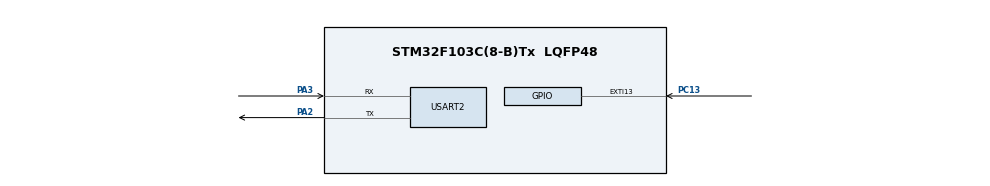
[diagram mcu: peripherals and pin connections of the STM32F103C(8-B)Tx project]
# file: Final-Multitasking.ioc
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Dma.Request0=USART2_RX
Dma.USART2_RX.0.Direction=DMA_PERIPH_TO_MEMORY
Dma.USART2_RX.0.Instance=DMA1_Channel6
Dma.USART2_RX.0.MemDataAlignment=DMA_MDATAALIGN_BYTE
Dma.USART2_RX.0.MemInc=DMA_MINC_ENABLE
Dma.USART2_RX.0.Mode=DMA_NORMAL
Dma.USART2_RX.0.PeriphDataAlignment=DMA_PDATAALIGN_BYTE
Dma.USART2_RX.0.PeriphInc=DMA_PINC_DISABLE
Dma.USART2_RX.0.Priority=DMA_PRIORITY_LOW
FREERTOS.Tasks01=defaultTask,0,128,StartDefaultTask,Default,NULL,Dynamic,NULL,NULL
Mcu.Family=STM32F1
Mcu.Name=STM32F103C(8-B)Tx
Mcu.Package=LQFP48
NVIC.DMA1_Channel6_IRQn=true\:5\:0\:false\:false\:true\:true\:false\:true\:true
NVIC.PriorityGroup=NVIC_PRIORITYGROUP_4
NVIC.TIM4_IRQn=true\:15\:0\:false\:false\:true\:false\:false\:true\:true
NVIC.TimeBase=TIM4_IRQn
NVIC.TimeBaseIP=TIM4
NVIC.USART2_IRQn=true\:5\:0\:false\:false\:true\:true\:true\:true\:true
PA13.Mode=Serial_Wire
PA13.Signal=SYS_JTMS-SWDIO
PA14.Mode=Serial_Wire
PA14.Signal=SYS_JTCK-SWCLK
PA2.Mode=Asynchronous
PA2.Signal=USART2_TX
PA3.Mode=Asynchronous
PA3.Signal=USART2_RX
PC13-TAMPER-RTC.GPIO_ModeDefaultEXTI=GPIO_MODE_IT_FALLING
PC13-TAMPER-RTC.GPIO_PuPd=GPIO_PULLUP
PC13-TAMPER-RTC.Signal=GPXTI13
ProjectManager.HeapSize=0x200
ProjectManager.StackSize=0x400
ProjectManager.TargetToolchain=MDK-ARM V5.32
RCC.APB1Freq_Value=8000000
RCC.APB2Freq_Value=8000000
USART2.VirtualMode=VM_ASYNC
VP_FREERTOS_VS_CMSIS_V1.Mode=CMSIS_V1
VP_SYS_VS_tim4.Mode=TIM4
board=custom

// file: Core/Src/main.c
/* USER CODE BEGIN Header */
/**
  ******************************************************************************
  * @file           : main.c
  * @brief          : Main program body
  ******************************************************************************
  * @attention
  *
  * Copyright (c) 2023 STMicroelectronics.
  * All rights reserved.
  *
  * This software is licensed under terms that can be found in the LICENSE file
  * in the root directory of this software component.
  * If no LICENSE file comes with this software, it is provided AS-IS.
  *
  ******************************************************************************
  */
/* USER CODE END Header */
#include "main.h"
#include "cmsis_os.h"

/* USER CODE BEGIN Includes */
#include "stdio.h"
#include "string.h"
/* USER CODE END Includes */

/* USER CODE BEGIN PTD */
typedef struct{
  uint8_t id;
  uint8_t command;
  uint8_t Frequency[2];
  uint8_t Threshold[3];
}myUartQueueData_t;

typedef struct{
  uint8_t id;
	uint8_t temp;
  uint8_t humi;
  uint8_t distance;
}myQueueData_t;

/* USER CODE END PTD */

/* USER CODE BEGIN PD */
#define TransmitBuff_SIZE	35
#define ReceiveBuff_SIZE	10
#define MainBuff_SIZE		8
#define Queue_SIZE			3
/* USER CODE END PD */

UART_HandleTypeDef huart2;
DMA_HandleTypeDef hdma_usart2_rx;

osThreadId defaultTaskHandle;
/* USER CODE BEGIN PV */
osThreadId DHTTaskHandle;
osThreadId HCSR04TaskHandle;
osThreadId LCDTaskHandle;
osThreadId UARTTaskHandle;
osThreadId ButtonTaskHandle;
osThreadId ThresholdTaskHandle;

osMessageQId myQueue01Handle;
osMessageQId myQueue02Handle;

/* Data of DHT11 Sensor */
float temp = 0;
float humi = 0;
uint8_t Rh_byte1, Rh_byte2, Temp_byte1, Temp_byte2;
uint16_t SUM, RH, TEMP;
uint8_t Presence = 0;

/* Data line of LCD1602*/
char data_line_1[16];
char data_line_2[16];

/* Data of HC-SR04 Sensor */
uint32_t IC_Val1 = 0;
uint32_t IC_Val2 = 0;
uint32_t Difference = 0;
uint8_t Is_First_Captured = 0;  // is the first value captured ?
uint8_t Distance  = 0;

/* Buffer Array */
uint8_t RxBuffer[ReceiveBuff_SIZE];
uint8_t TxBuffer[TransmitBuff_SIZE];
uint8_t MainBuffer[MainBuff_SIZE];

/* Period Time */
uint8_t DHT11_transmit_period;
uint8_t HCSR04_transmit_period;

/* Temperature Threshold */
uint8_t temp_threshold;

/* Humidity Threshold */
uint8_t humi_threshold;

/* Distance Threshold */
uint8_t dist_threshold;

/* Etc .. */
uint8_t cmd_index = 1;
uint8_t len = 0;

uint32_t start_tick = 0;
uint32_t stop_tick = 0;
uint32_t execute_tick = 0;

bool read_sensor_flag = 0;

uint16_t Count = 0;
uint16_t cnt = 0;
uint16_t cnt_1 = 0;
uint8_t isr_cnt = 0;

/* USER CODE END PV */

void SystemClock_Config(void);
static void MX_GPIO_Init(void);
static void MX_DMA_Init(void);
static void MX_USART2_UART_Init(void);
void StartDefaultTask(void const * argument);

/* USER CODE BEGIN PFP */
void DHTTask(void *Param);
void HCSR04Task(void *Param);
void LCDTask(void *Param);
void UARTTask(void *Param);
void ButtonTask(void *Param);
void ThresholdTask(void *Param);
uint8_t Rx_data[2];
/* USER CODE END PFP */

/* USER CODE BEGIN 0 */
#ifdef __GNUC__
#define PUTCHAR_PROTOTYPE int __io_putchar(int ch)
#else
#define PUTCHAR_PROTOTYPE int fputc(int ch, FILE *f)
#endif /* __GNUC__ */

/**
  * @brief  Retargets the C library printf function to the USART.
  * @param  None
  * @retval None
  */
PUTCHAR_PROTOTYPE
{
  HAL_UART_Transmit(&huart2, (uint8_t *)&ch, 1, HAL_MAX_DELAY);
  return ch;
}
/* USER CODE END 0 */

int main(void)
{

  /* MCU Configuration--------------------------------------------------------*/

  /* Reset of all peripherals, Initializes the Flash interface and the Systick. */
  HAL_Init();

  /* Configure the system clock */
  SystemClock_Config();

  /* Initialize all configured peripherals */
  MX_GPIO_Init();
  MX_DMA_Init();
  MX_USART2_UART_Init();

  /* Create the thread(s) */
  /* definition and creation of defaultTask */

  /* USER CODE BEGIN RTOS_THREADS */

  osMailQDef(myQueue01, 14, myQueueData_t);
  myQueue01Handle = osMailCreate(osMailQ(myQueue01), NULL);

  osMailQDef(myQueue02, 14, myUartQueueData_t);
  myQueue02Handle = osMailCreate(osMailQ(myQueue02), NULL);

  osThreadDef(DHTTask, osPriorityNormal, 0, 128*4);
  DHTTaskHandle  = osThreadCreate(DHTTask, NULL);

  osThreadDef(HCSR04Task, osPriorityBelowNormal, 0, 128*4);
  HCSR04TaskHandle  = osThreadCreate(HCSR04Task, NULL);

  osThreadDef(LCDTask, osPriorityAboveNormal, 0, 128*4);
  LCDTaskHandle  = osThreadCreate(DHTTask, NULL);

  osThreadDef(UARTTask, osPriorityAboveNormal, 0, 128*4);
  UARTTaskHandle  = osThreadCreate(UARTTask, NULL);

  osThreadDef(ButtonTask, osPriorityAboveNormal, 0, 128*4);
  ButtonTaskHandle  = osThreadCreate(ButtonTask, NULL);

  osThreadDef(ThresholdTask, osPriorityAboveNormal, 0, 128*4);
  ThresholdTaskHandle  = osThreadCreate(ThresholdTask, NULL);
  /* add threads, ... */
  /* USER CODE END RTOS_THREADS */

  /* Start scheduler */
  osKernelStart();

  /* We should never get here as control is now taken by the scheduler */
  /* Infinite loop */
  while (1)
  {

  }
}

void SystemClock_Config(void)
{
  RCC_OscInitTypeDef RCC_OscInitStruct = {0};
  RCC_ClkInitTypeDef RCC_ClkInitStruct = {0};

  /** Initializes the RCC Oscillators according to the specified parameters
  * in the RCC_OscInitTypeDef structure.
  */
  RCC_OscInitStruct.OscillatorType = RCC_OSCILLATORTYPE_HSI;
  RCC_OscInitStruct.HSIState = RCC_HSI_ON;
  RCC_OscInitStruct.HSICalibrationValue = RCC_HSICALIBRATION_DEFAULT;
  RCC_OscInitStruct.PLL.PLLState = RCC_PLL_NONE;
  if (HAL_RCC_OscConfig(&RCC_OscInitStruct) != HAL_OK)
  {
    Error_Handler();
  }

  /** Initializes the CPU, AHB and APB buses clocks
  */
  RCC_ClkInitStruct.ClockType = RCC_CLOCKTYPE_HCLK|RCC_CLOCKTYPE_SYSCLK
                              |RCC_CLOCKTYPE_PCLK1|RCC_CLOCKTYPE_PCLK2;
  RCC_ClkInitStruct.SYSCLKSource = RCC_SYSCLKSOURCE_HSI;
  RCC_ClkInitStruct.AHBCLKDivider = RCC_SYSCLK_DIV1;
  RCC_ClkInitStruct.APB1CLKDivider = RCC_HCLK_DIV1;
  RCC_ClkInitStruct.APB2CLKDivider = RCC_HCLK_DIV1;

  if (HAL_RCC_ClockConfig(&RCC_ClkInitStruct, FLASH_LATENCY_0) != HAL_OK)
  {
    Error_Handler();
  }
}

static void MX_USART2_UART_Init(void)
{

  huart2.Instance = USART2;
  huart2.Init.BaudRate = 115200;
  huart2.Init.WordLength = UART_WORDLENGTH_8B;
  huart2.Init.StopBits = UART_STOPBITS_1;
  huart2.Init.Parity = UART_PARITY_NONE;
  huart2.Init.Mode = UART_MODE_TX_RX;
  huart2.Init.HwFlowCtl = UART_HWCONTROL_NONE;
  huart2.Init.OverSampling = UART_OVERSAMPLING_16;
  if (HAL_UART_Init(&huart2) != HAL_OK)
  {
    Error_Handler();
  }

}

static void MX_DMA_Init(void)
{

  /* DMA controller clock enable */
  __HAL_RCC_DMA1_CLK_ENABLE();

  /* DMA interrupt init */
  /* DMA1_Channel6_IRQn interrupt configuration */
  HAL_NVIC_SetPriority(DMA1_Channel6_IRQn, 5, 0);
  HAL_NVIC_EnableIRQ(DMA1_Channel6_IRQn);

}

static void MX_GPIO_Init(void)
{
  GPIO_InitTypeDef GPIO_InitStruct = {0};

  /* GPIO Ports Clock Enable */
  __HAL_RCC_GPIOC_CLK_ENABLE();
  __HAL_RCC_GPIOA_CLK_ENABLE();

  /*Configure GPIO pin : PC13 */
  GPIO_InitStruct.Pin = GPIO_PIN_13;
  GPIO_InitStruct.Mode = GPIO_MODE_IT_FALLING;
  GPIO_InitStruct.Pull = GPIO_PULLUP;
  HAL_GPIO_Init(GPIOC, &GPIO_InitStruct);

}

/* USER CODE BEGIN 4 */
// Xử lý ngắt nút nhấn
void HAL_GPIO_EXTI_Callback(uint16_t GPIO_Pin)
{
  BaseType_t xHigherPriority;
  xHigherPriority = xTaskResumeFromISR(ButtonTask);
  portEND_SWITCHING_ISR(xHigherPriority);
}
// Xử lý ngắt  UART, nhảy vào hàm
void HAL_UARTEx_RxEventCallback(UART_HandleTypeDef *huart, uint16_t Size){
	if(huart->Instance == USART2){
		for(size_t i = 0; i<Size-1; i++) {
			if(RxBuffer[i] == 0x00){
				memcpy(MainBuffer, &RxBuffer[i], Size-i);
				processRecCmd(Size-i);
				break;
			}
		}
		HAL_UARTEx_ReceiveToIdle_DMA(&huart2, RxBuffer, MainBuff_SIZE);
		__HAL_DMA_DISABLE_IT(&hdma_usart2_rx, DMA_IT_HT);
  // Gọi Task UART để xử lý
  BaseType_t xHigher = xTaskResumeFromISR(UARTTask);
  portEND_SWITCHING_ISR(xHigher);
	}
}
void HAL_UART_RxCpltCallback(UART_HandleTypeDef *huart)
{
  HAL_UART_Receive_IT(&huart2, &Rx_data, 1);
  BaseType_t xHigher = xTaskResumeFromISR(UARTTask);
  portEND_SWITCHING_ISR(xHigher);
}
// Task đọc và gửi nhiệt độ
void DHTTask(void *Param)
{
  uint8_t Frequency = 1000;
  uint8_t Threshold[2] = {100,100};

  osEvent Recv_Task_data; // nhận dữ liệu từ Queue02

  myQueueData_t *msg = osMailAlloc(myQueue01Handle, osWaitForever);
  msg->id = 1;
  while(1)
  {
// Nhận ngưỡng nhiệt, độ ẩm và chu kì từ Queue2
    Recv_Task_data = osMailGet(myQueue02Handle, 0);
    if (Recv_Task_data.status == osEventMail)
    {
      myUartQueueData_t *data = Recv_Task_data.value.p; // con trỏ đến cấu trúc lưu nhiệt độ, độ ẩm
      if(data->id == 1)                           // gửi cho Task DHT
      {
        Frequency = data->Frequency[0];           // chu kì DHT
        Threshold[0] = data->Threshold[0];        // Ngưỡng nhiệt
        Threshold[1] = data->Threshold[1];        // Ngưỡng độ ẩm
        osMailFree(myQueue02Handle, data);
      }
    }

// Đưa nhiệt độ, độ ẩm vào Queue01 để hiển thị LCD
   msg->temp = temp;      // biến nhiệt độ đo được
   msg->humi = humi;
   osMailPut(myQueue01Handle, msg);

// Chu Kì
   osDelay(Frequency);
  }
}
// Task đọc và gửi khoảng cách
void HCSR04Task(void *Param)
{
  uint8_t Frequency = 1000;
  uint8_t Threshold = 100;

  osEvent Recv_Task_data; // nhận dữ liệu từ Queue02
  myQueueData_t *msg = osMailAlloc(myQueue01Handle, osWaitForever);
  msg->id = 2;
  while(1)
  {
// Nhận ngưỡng khoảng cách, chu kì từ Queue2
    Recv_Task_data = osMailGet(myQueue02Handle, 0);
    if (Recv_Task_data.status == osEventMail)
    {
      myUartQueueData_t *data = Recv_Task_data.value.p; // con trỏ đến cấu trúc lưu nhiệt độ, độ ẩm
      if(data->id == 2)                           // gửi cho Task HCSR04
      {
        Frequency = data->Frequency[0];           // chu kì
        Threshold = data->Threshold[2];           // Ngưỡng khoảng cách
        osMailFree(myQueue02Handle, data);
      }
    }
// Đưa khoảng cách vào queue01 để hiển thị LCD
    msg->distance = Distance;
    osMailPut(myQueue01Handle, msg);
  }

// Chu kỳ
osDelay(Frequency);
}
// Task hiển thị LCD
void LCDTask(void *Param)
{
  osEvent Recv_Task_data; // nhận dữ liệu từ Queue01
  while(1)
  {
    uint8_t temp, humi, distance;
    Recv_Task_data = osMailGet(myQueue01Handle, osWaitForever);
    myQueueData_t *data = Recv_Task_data.value.p; // con trỏ đến cấu trúc lưu nhiệt độ, độ ẩm, khoảng cách
    if(data->id == 1) // Nhận nhiệt độ độ ẩm
    {
      temp = data->temp;
      humi = data->humi;
    }
    else              // Nhận Khoảng cách
    {
      distance = data->distance;
    }
    // Xử lý hiển thị

    // nhận xong phải giải phóng
    osMailFree(myQueue01Handle, data);
  }
}
// Task xử lý khi nhân được ngắt UART
// Nhận dữ liệu và cập nhật ngưỡng vào Queue2 để các task khác xử lý
// Thêm 1 task ngưỡng, dùng suspend và resume
void UARTTask(void *Param)
{
  while(1)
  {
    vTaskSuspend(NULL);
// Đưa các biến Command; Frequency; Threshold vào Queue2 để các task khác xử lý
    myUartQueueData_t *msg = osMailAlloc(myQueue02Handle, osWaitForever);
// gửi đến DHTTask (Đang để Task DHT có mức ưu tiên cao hơn)
    msg->id = 1;                   // gửi đến DHTTask
    msg->Frequency[0] = 1;         // chu kì DHTTask
    msg->Threshold[0] = 1;         // Ngưỡng nhiệt
    msg->Threshold[1] = 1;         // Ngưỡng độ ẩm
    osMailPut(myQueue02Handle, msg);
// gửi đến HCSR04Task
    myUartQueueData_t *msg1 = osMailAlloc(myQueue02Handle, osWaitForever);
    msg1->id = 2;                   // gửi đến HCSR04Task
    msg1->Frequency[1] = 1;         // chu kì HCSR04ask
    msg1->Threshold[2] = 1;         // Ngưỡng khoảng cách
    osMailPut(myQueue02Handle, msg1);
// Xử lý command
  }
}
//Task xử lý khi nhấn nút
void ButtonTask(void *Param)
{
  while(1)
  {
    vTaskSuspend(NULL);
    printf("hello from AboveNormal Task\n");
  }
}

//Task xử lý ngưỡng
void ThresholdTask(void *Param)
{
  while(1)
  {
    vTaskSuspend(NULL);
    printf("hello from AboveNormal Task\n");
  }
}
/* USER CODE END 4 */

void HAL_TIM_PeriodElapsedCallback(TIM_HandleTypeDef *htim)
{
  if (htim->Instance == TIM4) {
    HAL_IncTick();
  }
}

void Error_Handler(void)
{
  __disable_irq();
  while (1)
  {
  }
}
